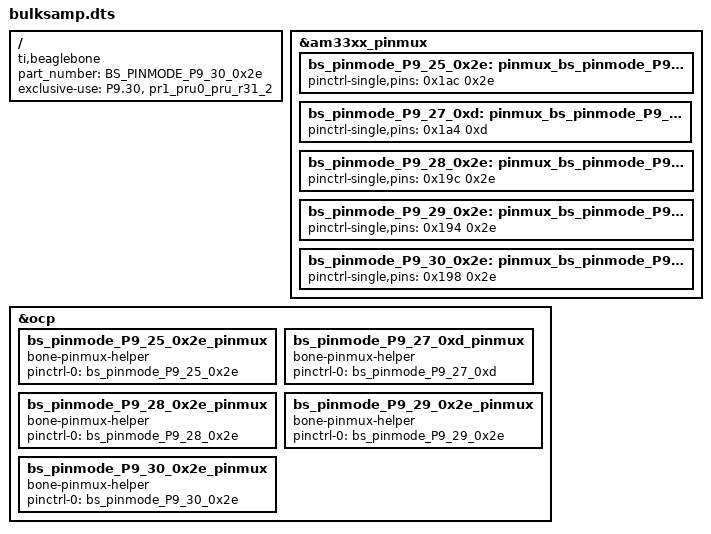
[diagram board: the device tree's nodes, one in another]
/*
  p9_25 as pr1_pru0_pru_r31_7
 */

/dts-v1/;
/plugin/;

/{
    compatible = "ti,beaglebone", "ti,beaglebone-black";
    part_number = "BS_PINMODE_P9_25_0x2e";

    exclusive-use =
        "P9.25",
        "pr1_pru0_pru_r31_7";

    fragment@0 {
        target = <&am33xx_pinmux>;
        __overlay__ {
            bs_pinmode_P9_25_0x2e: pinmux_bs_pinmode_P9_25_0x2e {
                pinctrl-single,pins = <0x1ac 0x2e>;
            };
        };
    };

    fragment@1 {
        target = <&ocp>;
        __overlay__ {
            bs_pinmode_P9_25_0x2e_pinmux {
                compatible = "bone-pinmux-helper";
                status = "okay";
                pinctrl-names = "default";
                pinctrl-0 = <&bs_pinmode_P9_25_0x2e>;
            };
        };
    };
};

/*
 * p9.27 pr1_pru0_pru_r30_5 clock out
 */

/{
    compatible = "ti,beaglebone", "ti,beaglebone-black";
    part_number = "BS_PINMODE_P9_27_0xd";

    exclusive-use =
        "P9.27",
        "pr1_pru0_pru_r30_5";

    fragment@0 {
        target = <&am33xx_pinmux>;
        __overlay__ {
            bs_pinmode_P9_27_0xd: pinmux_bs_pinmode_P9_27_0xd {
                pinctrl-single,pins = <0x1a4 0xd>;
            };
        };
    };

    fragment@1 {
        target = <&ocp>;
        __overlay__ {
            bs_pinmode_P9_27_0xd_pinmux {
                compatible = "bone-pinmux-helper";
                status = "okay";
                pinctrl-names = "default";
                pinctrl-0 = <&bs_pinmode_P9_27_0xd>;
            };
        };
    };
};


/*
  p9_28 as pr1_pru0_pru_r31_3
 */

/{
    compatible = "ti,beaglebone", "ti,beaglebone-black";
    part_number = "BS_PINMODE_P9_28_0x2e";

    exclusive-use =
        "P9.28",
        "pr1_pru0_pru_r31_3";

    fragment@0 {
        target = <&am33xx_pinmux>;
        __overlay__ {
            bs_pinmode_P9_28_0x2e: pinmux_bs_pinmode_P9_28_0x2e {
                pinctrl-single,pins = <0x19c 0x2e>;
            };
        };
    };

    fragment@1 {
        target = <&ocp>;
        __overlay__ {
            bs_pinmode_P9_28_0x2e_pinmux {
                compatible = "bone-pinmux-helper";
                status = "okay";
                pinctrl-names = "default";
                pinctrl-0 = <&bs_pinmode_P9_28_0x2e>;
            };
        };
    };
};

/*
  p9_29 as pr1_pru0_pru_r31_1
 */

/{
    compatible = "ti,beaglebone", "ti,beaglebone-black";
    part_number = "BS_PINMODE_P9_29_0x2e";

    exclusive-use =
        "P9.29",
        "pr1_pru0_pru_r31_1";

    fragment@0 {
        target = <&am33xx_pinmux>;
        __overlay__ {
            bs_pinmode_P9_29_0x2e: pinmux_bs_pinmode_P9_29_0x2e {
                pinctrl-single,pins = <0x194 0x2e>;
            };
        };
    };

    fragment@1 {
        target = <&ocp>;
        __overlay__ {
            bs_pinmode_P9_29_0x2e_pinmux {
                compatible = "bone-pinmux-helper";
                status = "okay";
                pinctrl-names = "default";
                pinctrl-0 = <&bs_pinmode_P9_29_0x2e>;
            };
        };
    };
};

/*
  p9_30 as pr1_pru0_pru_r31_2
 */

/{
    compatible = "ti,beaglebone", "ti,beaglebone-black";
    part_number = "BS_PINMODE_P9_30_0x2e";

    exclusive-use =
        "P9.30",
        "pr1_pru0_pru_r31_2";

    fragment@0 {
        target = <&am33xx_pinmux>;
        __overlay__ {
            bs_pinmode_P9_30_0x2e: pinmux_bs_pinmode_P9_30_0x2e {
                pinctrl-single,pins = <0x198 0x2e>;
            };
        };
    };

    fragment@1 {
        target = <&ocp>;
        __overlay__ {
            bs_pinmode_P9_30_0x2e_pinmux {
                compatible = "bone-pinmux-helper";
                status = "okay";
                pinctrl-names = "default";
                pinctrl-0 = <&bs_pinmode_P9_30_0x2e>;
            };
        };
    };
};

